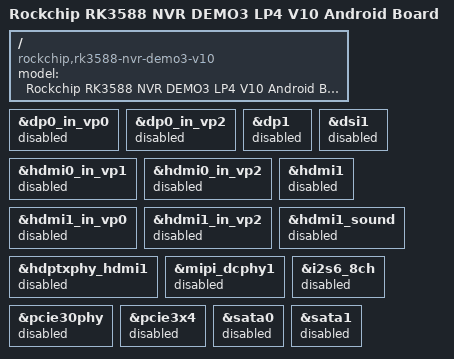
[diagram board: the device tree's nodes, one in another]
// SPDX-License-Identifier: (GPL-2.0+ OR MIT)
/*
 * Copyright (c) 2021 Rockchip Electronics Co., Ltd.
 *
 */

/dts-v1/;

#include "rk3588-nvr-demo3-v10.dtsi"
#include "rk3588-android.dtsi"

/ {
	model = "Rockchip RK3588 NVR DEMO3 LP4 V10 Android Board";
	compatible = "rockchip,rk3588-nvr-demo3-v10", "rockchip,rk3588";
};

&dp0_in_vp0 {
	status = "disabled";
};

&dp0_in_vp2 {
	status = "disabled";
};

&dp1 {
	status = "disabled";
};

&dsi1 {
	status = "disabled";
};

&hdmi0_in_vp1 {
	status = "disabled";
};

&hdmi0_in_vp2 {
	status = "disabled";
};

&hdmi1 {
	status = "disabled";
};

&hdmi1_in_vp0 {
	status = "disabled";
};

&hdmi1_in_vp2 {
	status = "disabled";
};

&hdmi1_sound {
	status = "disabled";
};

&hdptxphy_hdmi1 {
	status = "disabled";
};

&mipi_dcphy1 {
	status = "disabled";
};

&i2s6_8ch {
	status = "disabled";
};

&pcie30phy {
	status = "disabled";
};

&pcie3x4 {
	status = "disabled";
};

&sata0 {
	status = "disabled";
};

&sata1 {
	status = "disabled";
};

